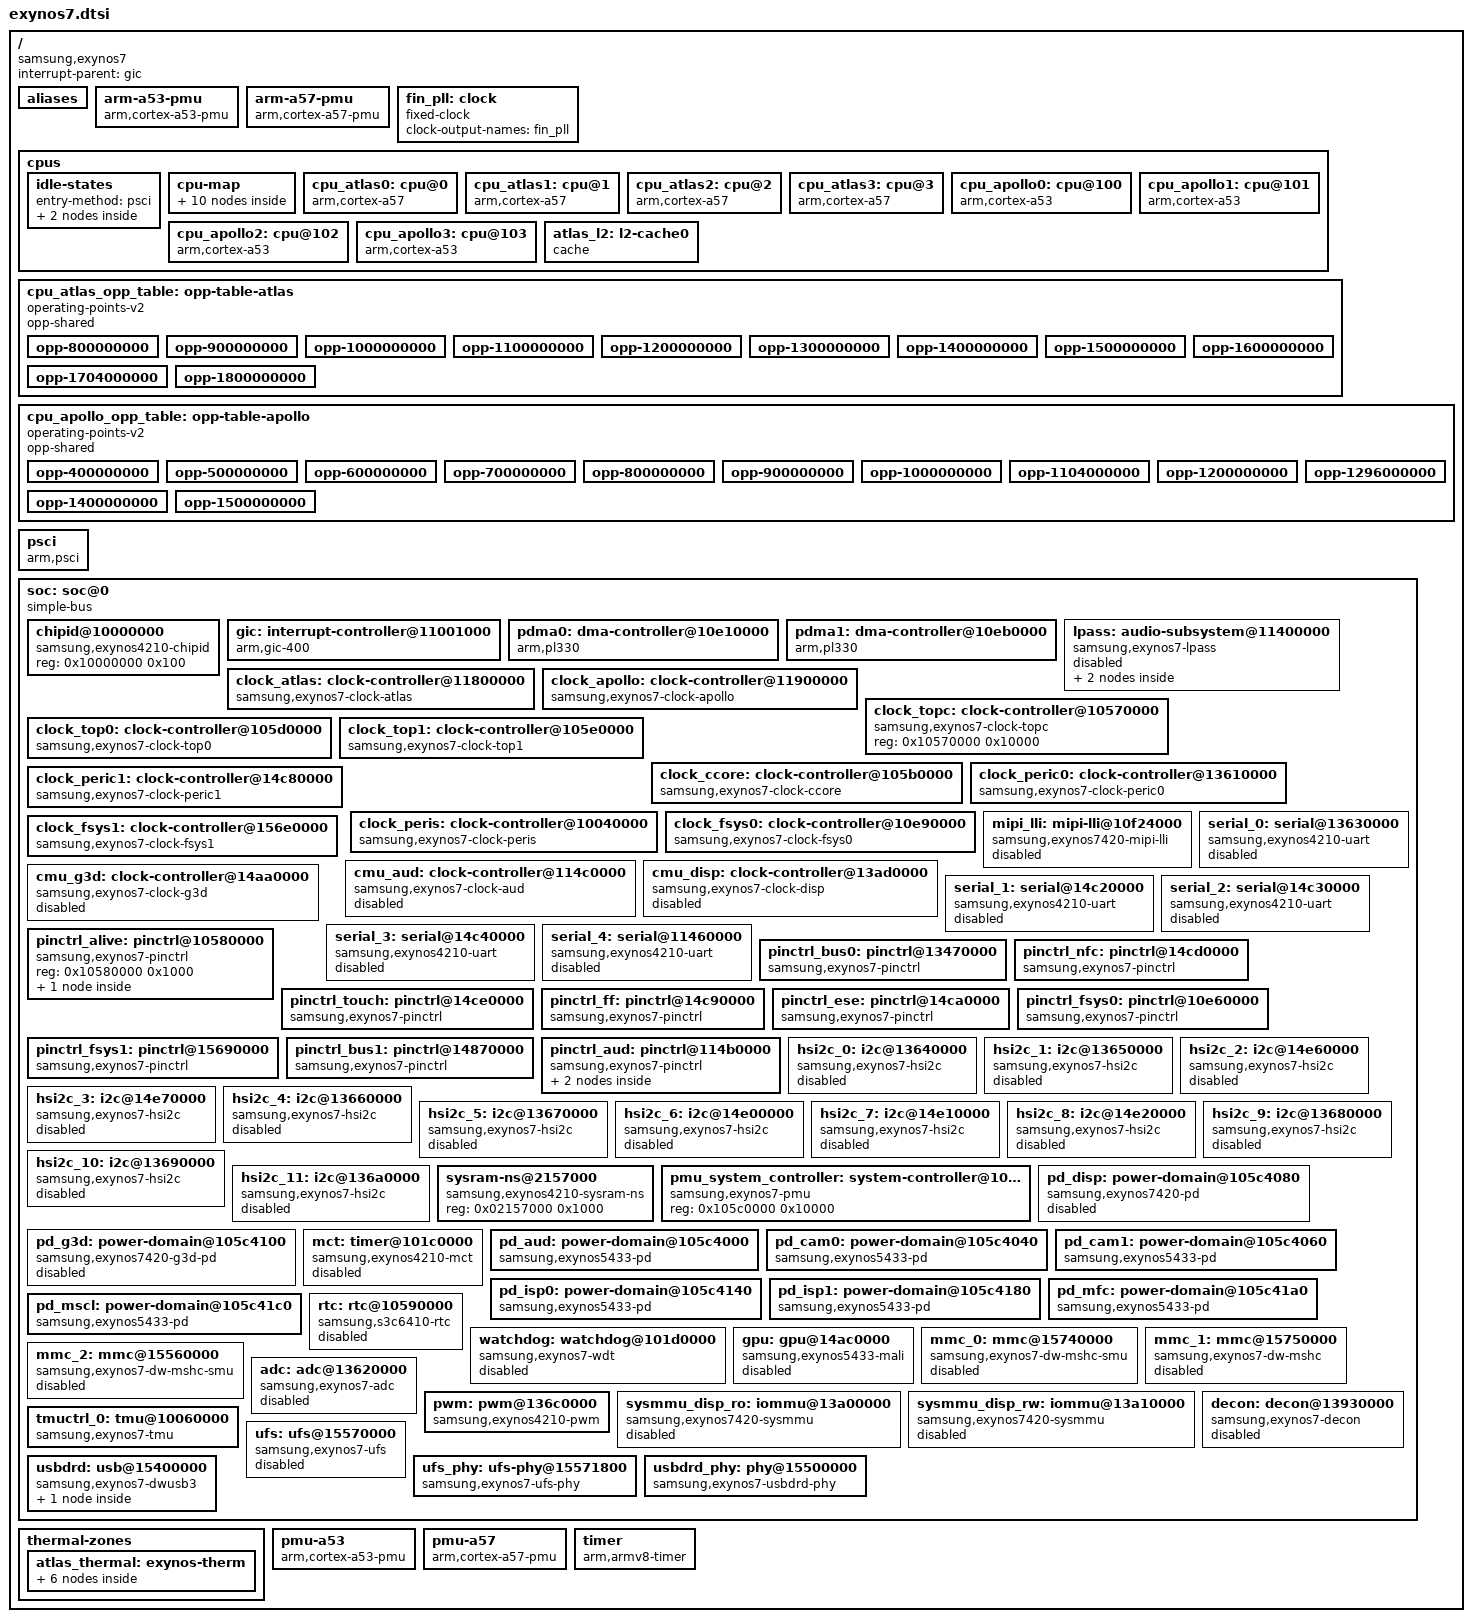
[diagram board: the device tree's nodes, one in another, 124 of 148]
// SPDX-License-Identifier: GPL-2.0
/*
 * Samsung Exynos7 SoC device tree source
 *
 * Copyright (c) 2014 Samsung Electronics Co., Ltd.
 *		http://www.samsung.com
 */

#include <dt-bindings/clock/exynos7-clk.h>
#include <dt-bindings/interrupt-controller/arm-gic.h>

/ {
	compatible = "samsung,exynos7";
	interrupt-parent = <&gic>;
	#address-cells = <2>;
	#size-cells = <2>;

	aliases {
		pinctrl0 = &pinctrl_alive;
		pinctrl1 = &pinctrl_bus0;
		pinctrl2 = &pinctrl_nfc;
		pinctrl3 = &pinctrl_touch;
		pinctrl4 = &pinctrl_ff;
		pinctrl5 = &pinctrl_ese;
		pinctrl6 = &pinctrl_fsys0;
		pinctrl7 = &pinctrl_fsys1;
		pinctrl8 = &pinctrl_bus1;
		pinctrl9 = &pinctrl_aud;
		tmuctrl0 = &tmuctrl_0;
	};

	arm-a53-pmu {
		compatible = "arm,cortex-a53-pmu";
		interrupts = <GIC_SPI 32 IRQ_TYPE_LEVEL_HIGH>,
			     <GIC_SPI 33 IRQ_TYPE_LEVEL_HIGH>,
			     <GIC_SPI 34 IRQ_TYPE_LEVEL_HIGH>,
			     <GIC_SPI 35 IRQ_TYPE_LEVEL_HIGH>;
		interrupt-affinity = <&cpu_apollo0>, <&cpu_apollo1>,
				     <&cpu_apollo2>, <&cpu_apollo3>;
	};

	arm-a57-pmu {
		compatible = "arm,cortex-a57-pmu";
		interrupts = <GIC_SPI 56 IRQ_TYPE_LEVEL_HIGH>,
			     <GIC_SPI 57 IRQ_TYPE_LEVEL_HIGH>,
			     <GIC_SPI 58 IRQ_TYPE_LEVEL_HIGH>,
			     <GIC_SPI 59 IRQ_TYPE_LEVEL_HIGH>;
		interrupt-affinity = <&cpu_atlas0>, <&cpu_atlas1>,
				     <&cpu_atlas2>, <&cpu_atlas3>;
	};

	fin_pll: clock {
		/* XXTI */
		compatible = "fixed-clock";
		clock-output-names = "fin_pll";
		#clock-cells = <0>;
	};

	cpus {
		#address-cells = <1>;
		#size-cells = <0>;

		/*
		 * Core power-down (C2) through PSCI 0.1 CPU_SUSPEND. The
		 * parameter asks for a power-down state, so the kernel saves
		 * the core's context; the PMU notifier in exynos-pmu clears
		 * the core's LOCAL_PWR_CFG for it. Residencies are the stock
		 * kernel's.
		 */
		idle-states {
			entry-method = "psci";

			CPU_C2_A57: cpu-c2-a57 {
				compatible = "arm,idle-state";
				arm,psci-suspend-param = <0x00010000>;
				entry-latency-us = <30>;
				exit-latency-us = <70>;
				min-residency-us = <2000>;
			};

			CPU_C2_A53: cpu-c2-a53 {
				compatible = "arm,idle-state";
				arm,psci-suspend-param = <0x00010000>;
				entry-latency-us = <30>;
				exit-latency-us = <70>;
				min-residency-us = <750>;
			};
		};

		/*
		 * Two clusters. Without the map and the per-MHz capacities the
		 * scheduler treats the eight cores as equal one-core clusters.
		 * The A53's efficiency, 677 per MHz to the A57's 1000, is the
		 * CoreMark value measured on a G920F (nk7420 calibration). With
		 * the top OPPs, 1.5 GHz on the A53s and 1.8 GHz on the A57s, it
		 * gives capacities of 578 and 1024.
		 */
		cpu-map {
			cluster0 {
				core0 { cpu = <&cpu_atlas0>; };
				core1 { cpu = <&cpu_atlas1>; };
				core2 { cpu = <&cpu_atlas2>; };
				core3 { cpu = <&cpu_atlas3>; };
			};

			cluster1 {
				core0 { cpu = <&cpu_apollo0>; };
				core1 { cpu = <&cpu_apollo1>; };
				core2 { cpu = <&cpu_apollo2>; };
				core3 { cpu = <&cpu_apollo3>; };
			};
		};

		/*
		 * Linux makes the boot CPU, the first A53 (MPIDR 0x100), CPU 0 and
		 * numbers the others in node order. Listing the A57s first gives
		 * A57 = CPUs 1-4 and A53 = CPUs 0 and 5-7, the numbering the
		 * cpufreq, memlat and power work on this branch was measured with.
		 */
		cpu_atlas0: cpu@0 {
			device_type = "cpu";
			compatible = "arm,cortex-a57";
			reg = <0x0>;
			enable-method = "psci";
			cpu-idle-states = <&CPU_C2_A57>;
			capacity-dmips-mhz = <1000>;
			clocks = <&clock_atlas CLK_SCLK_ATLAS>;
			operating-points-v2 = <&cpu_atlas_opp_table>;
			#cooling-cells = <2>;
			i-cache-size = <0xc000>;
			i-cache-line-size = <64>;
			i-cache-sets = <256>;
			d-cache-size = <0x8000>;
			d-cache-line-size = <64>;
			d-cache-sets = <256>;
			next-level-cache = <&atlas_l2>;
		};

		cpu_atlas1: cpu@1 {
			device_type = "cpu";
			compatible = "arm,cortex-a57";
			reg = <0x1>;
			enable-method = "psci";
			cpu-idle-states = <&CPU_C2_A57>;
			capacity-dmips-mhz = <1000>;
			clocks = <&clock_atlas CLK_SCLK_ATLAS>;
			operating-points-v2 = <&cpu_atlas_opp_table>;
			#cooling-cells = <2>;
			i-cache-size = <0xc000>;
			i-cache-line-size = <64>;
			i-cache-sets = <256>;
			d-cache-size = <0x8000>;
			d-cache-line-size = <64>;
			d-cache-sets = <256>;
			next-level-cache = <&atlas_l2>;
		};

		cpu_atlas2: cpu@2 {
			device_type = "cpu";
			compatible = "arm,cortex-a57";
			reg = <0x2>;
			enable-method = "psci";
			cpu-idle-states = <&CPU_C2_A57>;
			capacity-dmips-mhz = <1000>;
			clocks = <&clock_atlas CLK_SCLK_ATLAS>;
			operating-points-v2 = <&cpu_atlas_opp_table>;
			#cooling-cells = <2>;
			i-cache-size = <0xc000>;
			i-cache-line-size = <64>;
			i-cache-sets = <256>;
			d-cache-size = <0x8000>;
			d-cache-line-size = <64>;
			d-cache-sets = <256>;
			next-level-cache = <&atlas_l2>;
		};

		cpu_atlas3: cpu@3 {
			device_type = "cpu";
			compatible = "arm,cortex-a57";
			reg = <0x3>;
			enable-method = "psci";
			cpu-idle-states = <&CPU_C2_A57>;
			capacity-dmips-mhz = <1000>;
			clocks = <&clock_atlas CLK_SCLK_ATLAS>;
			operating-points-v2 = <&cpu_atlas_opp_table>;
			#cooling-cells = <2>;
			i-cache-size = <0xc000>;
			i-cache-line-size = <64>;
			i-cache-sets = <256>;
			d-cache-size = <0x8000>;
			d-cache-line-size = <64>;
			d-cache-sets = <256>;
			next-level-cache = <&atlas_l2>;
		};

		cpu_apollo0: cpu@100 {
			device_type = "cpu";
			compatible = "arm,cortex-a53";
			reg = <0x100>;
			enable-method = "psci";
			cpu-idle-states = <&CPU_C2_A53>;
			capacity-dmips-mhz = <677>;
			clocks = <&clock_apollo CLK_SCLK_APOLLO>;
			operating-points-v2 = <&cpu_apollo_opp_table>;
			#cooling-cells = <2>;
		};

		cpu_apollo1: cpu@101 {
			device_type = "cpu";
			compatible = "arm,cortex-a53";
			reg = <0x101>;
			enable-method = "psci";
			cpu-idle-states = <&CPU_C2_A53>;
			capacity-dmips-mhz = <677>;
			clocks = <&clock_apollo CLK_SCLK_APOLLO>;
			operating-points-v2 = <&cpu_apollo_opp_table>;
			#cooling-cells = <2>;
		};

		cpu_apollo2: cpu@102 {
			device_type = "cpu";
			compatible = "arm,cortex-a53";
			reg = <0x102>;
			enable-method = "psci";
			cpu-idle-states = <&CPU_C2_A53>;
			capacity-dmips-mhz = <677>;
			clocks = <&clock_apollo CLK_SCLK_APOLLO>;
			operating-points-v2 = <&cpu_apollo_opp_table>;
			#cooling-cells = <2>;
		};

		cpu_apollo3: cpu@103 {
			device_type = "cpu";
			compatible = "arm,cortex-a53";
			reg = <0x103>;
			enable-method = "psci";
			cpu-idle-states = <&CPU_C2_A53>;
			capacity-dmips-mhz = <677>;
			clocks = <&clock_apollo CLK_SCLK_APOLLO>;
			operating-points-v2 = <&cpu_apollo_opp_table>;
			#cooling-cells = <2>;
		};

		atlas_l2: l2-cache0 {
			compatible = "cache";
			cache-level = <2>;
			cache-unified;
			cache-size = <0x200000>;
			cache-line-size = <64>;
			cache-sets = <2048>;
		};
	};

	/*
	 * Cluster DVFS: the stock enabled ranges with the stock fallback
	 * voltages, which are at or above every fused ASV group. Atlas stops
	 * at 1.8 GHz while the PMIC's SRAM-rail tracking is left as S-Boot
	 * programmed it; above 1.125 V it must be switched.
	 *
	 * opp-microwatt is the energy model: per-core power measured on a
	 * G920F (calibration run 20260809T115944Z), plus a quarter of the
	 * measured shared-cluster power, since the energy model has no
	 * cluster term. It was measured at that phone's fused ASV voltages,
	 * so absolute power here is somewhat low; the ratio between the
	 * clusters, which energy-aware scheduling uses, is what matters.
	 */
	cpu_atlas_opp_table: opp-table-atlas {
		compatible = "operating-points-v2";
		opp-shared;

		opp-800000000 {
			opp-hz = /bits/ 64 <800000000>;
			opp-microvolt = <825000>;
			opp-microwatt = <261750>;
			clock-latency-ns = <500000>;
		};

		opp-900000000 {
			opp-hz = /bits/ 64 <900000000>;
			opp-microvolt = <850000>;
			opp-microwatt = <304500>;
			clock-latency-ns = <500000>;
		};

		opp-1000000000 {
			opp-hz = /bits/ 64 <1000000000>;
			opp-microvolt = <875000>;
			opp-microwatt = <359500>;
			clock-latency-ns = <500000>;
		};

		opp-1100000000 {
			opp-hz = /bits/ 64 <1100000000>;
			opp-microvolt = <900000>;
			opp-microwatt = <428250>;
			clock-latency-ns = <500000>;
		};

		opp-1200000000 {
			opp-hz = /bits/ 64 <1200000000>;
			opp-microvolt = <925000>;
			opp-microwatt = <493250>;
			clock-latency-ns = <500000>;
		};

		opp-1300000000 {
			opp-hz = /bits/ 64 <1300000000>;
			opp-microvolt = <950000>;
			opp-microwatt = <563250>;
			clock-latency-ns = <500000>;
		};

		opp-1400000000 {
			opp-hz = /bits/ 64 <1400000000>;
			opp-microvolt = <981250>;
			opp-microwatt = <654000>;
			clock-latency-ns = <500000>;
		};

		opp-1500000000 {
			opp-hz = /bits/ 64 <1500000000>;
			opp-microvolt = <1012500>;
			opp-microwatt = <737000>;
			clock-latency-ns = <500000>;
		};

		opp-1600000000 {
			opp-hz = /bits/ 64 <1600000000>;
			opp-microvolt = <1043750>;
			opp-microwatt = <855000>;
			clock-latency-ns = <500000>;
		};

		opp-1704000000 {
			opp-hz = /bits/ 64 <1704000000>;
			opp-microvolt = <1081250>;
			opp-microwatt = <989750>;
			clock-latency-ns = <500000>;
		};

		opp-1800000000 {
			opp-hz = /bits/ 64 <1800000000>;
			opp-microvolt = <1118750>;
			opp-microwatt = <1156750>;
			clock-latency-ns = <500000>;
		};
	};

	cpu_apollo_opp_table: opp-table-apollo {
		compatible = "operating-points-v2";
		opp-shared;

		opp-400000000 {
			opp-hz = /bits/ 64 <400000000>;
			opp-microvolt = <675000>;
			opp-microwatt = <25000>;
			clock-latency-ns = <500000>;
		};

		opp-500000000 {
			opp-hz = /bits/ 64 <500000000>;
			opp-microvolt = <712500>;
			opp-microwatt = <35000>;
			clock-latency-ns = <500000>;
		};

		opp-600000000 {
			opp-hz = /bits/ 64 <600000000>;
			opp-microvolt = <750000>;
			opp-microwatt = <43000>;
			clock-latency-ns = <500000>;
		};

		opp-700000000 {
			opp-hz = /bits/ 64 <700000000>;
			opp-microvolt = <787500>;
			opp-microwatt = <54000>;
			clock-latency-ns = <500000>;
		};

		opp-800000000 {
			opp-hz = /bits/ 64 <800000000>;
			opp-microvolt = <825000>;
			opp-microwatt = <66000>;
			clock-latency-ns = <500000>;
		};

		opp-900000000 {
			opp-hz = /bits/ 64 <900000000>;
			opp-microvolt = <862500>;
			opp-microwatt = <81000>;
			clock-latency-ns = <500000>;
		};

		opp-1000000000 {
			opp-hz = /bits/ 64 <1000000000>;
			opp-microvolt = <900000>;
			opp-microwatt = <96000>;
			clock-latency-ns = <500000>;
		};

		opp-1104000000 {
			opp-hz = /bits/ 64 <1104000000>;
			opp-microvolt = <943750>;
			opp-microwatt = <117000>;
			clock-latency-ns = <500000>;
		};

		opp-1200000000 {
			opp-hz = /bits/ 64 <1200000000>;
			opp-microvolt = <981250>;
			opp-microwatt = <140250>;
			clock-latency-ns = <500000>;
		};

		opp-1296000000 {
			opp-hz = /bits/ 64 <1296000000>;
			opp-microvolt = <1018750>;
			opp-microwatt = <166250>;
			clock-latency-ns = <500000>;
		};

		opp-1400000000 {
			opp-hz = /bits/ 64 <1400000000>;
			opp-microvolt = <1068750>;
			opp-microwatt = <200250>;
			clock-latency-ns = <500000>;
		};

		opp-1500000000 {
			opp-hz = /bits/ 64 <1500000000>;
			opp-microvolt = <1118750>;
			opp-microwatt = <237250>;
			clock-latency-ns = <500000>;
		};
	};

	psci {
		compatible = "arm,psci";
		method = "smc";
		cpu_suspend = <0xc4000001>;
		cpu_off = <0x84000002>;
		cpu_on = <0xc4000003>;
	};

	soc: soc@0 {
		compatible = "simple-bus";
		#address-cells = <1>;
		#size-cells = <1>;
		ranges = <0 0 0 0x18000000>;

		chipid@10000000 {
			compatible = "samsung,exynos4210-chipid";
			reg = <0x10000000 0x100>;
		};

		gic: interrupt-controller@11001000 {
			compatible = "arm,gic-400";
			#interrupt-cells = <3>;
			#address-cells = <0>;
			interrupt-controller;
			reg = <0x11001000 0x1000>,
			      <0x11002000 0x2000>,
			      <0x11004000 0x2000>,
			      <0x11006000 0x2000>;
		};

		pdma0: dma-controller@10e10000 {
			compatible = "arm,pl330", "arm,primecell";
			reg = <0x10e10000 0x1000>;
			interrupts = <GIC_SPI 225 IRQ_TYPE_LEVEL_HIGH>;
			clocks = <&clock_fsys0 ACLK_PDMA0>;
			clock-names = "apb_pclk";
			#dma-cells = <1>;
		};

		pdma1: dma-controller@10eb0000 {
			compatible = "arm,pl330", "arm,primecell";
			reg = <0x10eb0000 0x1000>;
			interrupts = <GIC_SPI 226 IRQ_TYPE_LEVEL_HIGH>;
			clocks = <&clock_fsys0 ACLK_PDMA1>;
			clock-names = "apb_pclk";
			#dma-cells = <1>;
		};

		/*
		 * LPASS routes the DMA and I2S interrupts to the CPU and holds
		 * their resets. The UART at 0x11460000 (serial_4) is in the
		 * same block but stays outside this node; the exynos7 variant
		 * of the driver leaves it alone. The second reg is the AUD
		 * SysMMU, which the driver sets to bypass. The clocks keep the
		 * SysMMU and the bridge to the top bus, the ADMA's path out,
		 * running while LPASS is up.
		 */
		lpass: audio-subsystem@11400000 {
			compatible = "samsung,exynos7-lpass";
			reg = <0x11400000 0x100>, <0x114e0000 0x100>;
			clocks = <&cmu_aud PCLK_SMMU_AUD>,
				 <&cmu_aud ACLK_SMMU_AUD>,
				 <&cmu_aud ACLK_ACEL_LH_ASYNC_SI_TOP>;
			clock-names = "smmu_pclk", "smmu_aclk", "async_aclk";
			#address-cells = <1>;
			#size-cells = <1>;
			ranges;
			status = "disabled";

			adma: dma-controller@11420000 {
				compatible = "arm,pl330", "arm,primecell";
				reg = <0x11420000 0x1000>;
				interrupts = <GIC_SPI 97 IRQ_TYPE_LEVEL_HIGH>;
				clocks = <&cmu_aud ACLK_ADMA>;
				clock-names = "apb_pclk";
				#dma-cells = <1>;
			};

			i2s0: i2s@11440000 {
				compatible = "samsung,exynos7-i2s";
				reg = <0x11440000 0x100>;
				interrupts = <GIC_SPI 70 IRQ_TYPE_LEVEL_HIGH>;
				dmas = <&adma 0>, <&adma 2>;
				dma-names = "tx", "rx";
				clocks = <&cmu_aud PCLK_I2S>, <&cmu_aud SCLK_I2S>,
					 <&cmu_aud SCLK_I2S>;
				clock-names = "iis", "i2s_opclk0", "i2s_opclk1";
				#sound-dai-cells = <1>;
				status = "disabled";
			};
		};

		clock_atlas: clock-controller@11800000 {
			compatible = "samsung,exynos7-clock-atlas";
			reg = <0x11800000 0x2000>;
			#clock-cells = <1>;
			clocks = <&fin_pll>;
			clock-names = "fin_pll";
		};

		clock_apollo: clock-controller@11900000 {
			compatible = "samsung,exynos7-clock-apollo";
			reg = <0x11900000 0x2000>;
			#clock-cells = <1>;
			clocks = <&fin_pll>;
			clock-names = "fin_pll";
		};

		clock_topc: clock-controller@10570000 {
			compatible = "samsung,exynos7-clock-topc";
			reg = <0x10570000 0x10000>;
			#clock-cells = <1>;
		};

		clock_top0: clock-controller@105d0000 {
			compatible = "samsung,exynos7-clock-top0";
			reg = <0x105d0000 0xb000>;
			#clock-cells = <1>;
			clocks = <&fin_pll>, <&clock_topc DOUT_SCLK_BUS0_PLL>,
				 <&clock_topc DOUT_SCLK_BUS1_PLL>,
				 <&clock_topc DOUT_SCLK_CC_PLL>,
				 <&clock_topc DOUT_SCLK_MFC_PLL>,
				 <&clock_topc DOUT_SCLK_AUD_PLL>;
			clock-names = "fin_pll", "dout_sclk_bus0_pll",
				      "dout_sclk_bus1_pll", "dout_sclk_cc_pll",
				      "dout_sclk_mfc_pll", "dout_sclk_aud_pll";
		};

		clock_top1: clock-controller@105e0000 {
			compatible = "samsung,exynos7-clock-top1";
			reg = <0x105e0000 0xb000>;
			#clock-cells = <1>;
			clocks = <&fin_pll>, <&clock_topc DOUT_SCLK_BUS0_PLL>,
				 <&clock_topc DOUT_SCLK_BUS1_PLL>,
				 <&clock_topc DOUT_SCLK_CC_PLL>,
				 <&clock_topc DOUT_SCLK_MFC_PLL>;
			clock-names = "fin_pll", "dout_sclk_bus0_pll",
				      "dout_sclk_bus1_pll", "dout_sclk_cc_pll",
				      "dout_sclk_mfc_pll";
		};

		clock_ccore: clock-controller@105b0000 {
			compatible = "samsung,exynos7-clock-ccore";
			reg = <0x105b0000 0xd00>;
			#clock-cells = <1>;
			clocks = <&fin_pll>, <&clock_topc DOUT_ACLK_CCORE_133>;
			clock-names = "fin_pll", "dout_aclk_ccore_133";
		};

		clock_peric0: clock-controller@13610000 {
			compatible = "samsung,exynos7-clock-peric0";
			reg = <0x13610000 0xd00>;
			#clock-cells = <1>;
			clocks = <&fin_pll>, <&clock_top0 DOUT_ACLK_PERIC0>,
				 <&clock_top0 CLK_SCLK_UART0>;
			clock-names = "fin_pll", "dout_aclk_peric0_66",
				      "sclk_uart0";
		};

		clock_peric1: clock-controller@14c80000 {
			compatible = "samsung,exynos7-clock-peric1";
			reg = <0x14c80000 0xd00>;
			#clock-cells = <1>;
			clocks = <&fin_pll>,
				 <&clock_top0 DOUT_ACLK_PERIC1>,
				 <&clock_top0 CLK_SCLK_UART1>,
				 <&clock_top0 CLK_SCLK_UART2>,
				 <&clock_top0 CLK_SCLK_UART3>,
				 <&clock_top0 CLK_SCLK_SPI0>,
				 <&clock_top0 CLK_SCLK_SPI1>,
				 <&clock_top0 CLK_SCLK_SPI2>,
				 <&clock_top0 CLK_SCLK_SPI3>,
				 <&clock_top0 CLK_SCLK_SPI4>,
				 <&clock_top0 CLK_SCLK_I2S1>,
				 <&clock_top0 CLK_SCLK_PCM1>,
				 <&clock_top0 CLK_SCLK_SPDIF>;
			clock-names = "fin_pll",
				      "dout_aclk_peric1_66",
				      "sclk_uart1",
				      "sclk_uart2",
				      "sclk_uart3",
				      "sclk_spi0",
				      "sclk_spi1",
				      "sclk_spi2",
				      "sclk_spi3",
				      "sclk_spi4",
				      "sclk_i2s1",
				      "sclk_pcm1",
				      "sclk_spdif";
		};

		clock_peris: clock-controller@10040000 {
			compatible = "samsung,exynos7-clock-peris";
			reg = <0x10040000 0xd00>;
			#clock-cells = <1>;
			clocks = <&fin_pll>, <&clock_topc DOUT_ACLK_PERIS>;
			clock-names = "fin_pll", "dout_aclk_peris_66";
		};

		clock_fsys0: clock-controller@10e90000 {
			compatible = "samsung,exynos7-clock-fsys0";
			reg = <0x10e90000 0xd00>;
			#clock-cells = <1>;
			clocks = <&fin_pll>, <&clock_top1 DOUT_ACLK_FSYS0_200>,
				 <&clock_top1 DOUT_SCLK_MMC2>;
			clock-names = "fin_pll", "dout_aclk_fsys0_200",
				      "dout_sclk_mmc2";
		};

		/*
		 * MIPI-LLI to the modem CP. Register windows, interrupts and
		 * clocks from the stock tw70-stock exynos7420.dtsi node; the
		 * M-PHY (stock "mphy" child) is folded into "phy" and "pma".
		 * The combo PHY PMA at 0x10ed0000 is shared with PCIe channel 0,
		 * which this tree does not use. Boards add the IPC carve-out
		 * (memory-region) and the M-PHY settings.
		 */
		mipi_lli: mipi-lli@10f24000 {
			compatible = "samsung,exynos7420-mipi-lli";
			reg = <0x10f24000 0x4000>,
			      <0x10f34000 0x4000>,
			      <0x10050000 0x2000>,
			      <0x10f20000 0x4000>,
			      <0x10ed0000 0x200>;
			reg-names = "lli", "remote", "sysreg", "phy", "pma";
			interrupts = <GIC_SPI 208 IRQ_TYPE_LEVEL_HIGH>,
				     <GIC_SPI 209 IRQ_TYPE_LEVEL_HIGH>;
			interrupt-names = "lli", "sig";
			samsung,pmu-syscon = <&pmu_system_controller 0x724>;
			clocks = <&clock_fsys0 ACLK_XIU_MODEMX>,
				 <&clock_fsys0 ACLK_COMBO_PHY_MODEM_PCS_PCLK>,
				 <&clock_fsys0 SCLK_PHY_FSYS0>,
				 <&clock_fsys0 SCLK_COMBO_PHY_MODEM_26M>,
				 <&clock_fsys0 PCLK_ASYNC_COMBO_PHY_MODEM>,
				 <&clock_fsys0 ACLK_XIU_LLISFRX>,
				 <&clock_fsys0 ACLK_AXIUS_LLI_BE>,
				 <&clock_fsys0 ACLK_AXIUS_LLI_LL>,
				 <&clock_fsys0 ACLK_AXIUS_LLISFRX_LLILL>,
				 <&clock_fsys0 ACLK_AXIUS_LLISFRX_LLIBE>,
				 <&clock_fsys0 ACLK_LLI_SVC_LOC>,
				 <&clock_fsys0 ACLK_LLI_SVC_REM>,
				 <&clock_fsys0 ACLK_LLI_LL_INIT>,
				 <&clock_fsys0 ACLK_LLI_BE_INIT>,
				 <&clock_fsys0 ACLK_LLI_LL_TARG>,
				 <&clock_fsys0 ACLK_LLI_BE_TARG>,
				 <&clock_fsys0 PHYCLK_LLI_TX0_SYMBOL_USER>,
				 <&clock_fsys0 PHYCLK_LLI_RX0_SYMBOL_USER>;
			clock-names = "aclk_xiu_modemx",
				      "aclk_combo_phy_modem_pcs_pclk",
				      "sclk_phy_fsys0",
				      "sclk_combo_phy_modem_26m",
				      "pclk_async_combo_phy_modem",
				      "aclk_xiu_llisfrx",
				      "aclk_axius_lli_be",
				      "aclk_axius_lli_ll",
				      "aclk_axius_llisfrx_llill",
				      "aclk_axius_llisfrx_llibe",
				      "aclk_lli_svc_loc",
				      "aclk_lli_svc_rem",
				      "aclk_lli_ll_init",
				      "aclk_lli_be_init",
				      "aclk_lli_ll_targ",
				      "aclk_lli_be_targ",
				      "user_phyclk_lli_tx0_symbol",
				      "user_phyclk_lli_rx0_symbol";
			/*
			 * Stock USERMUX clocks: select the PHY-side symbol clocks.
			 * mout_sclk_phy_fsys0_user keeps the bootloader setting,
			 * because its parent sits in CMU_TOP1, which boards may
			 * leave unregistered.
			 */
			assigned-clocks = <&clock_fsys0 MOUT_PHYCLK_LLI_TX0_USER>,
					  <&clock_fsys0 MOUT_PHYCLK_LLI_RX0_USER>;
			assigned-clock-parents = <&clock_fsys0 PHYCLK_LLI_TX0>,
						 <&clock_fsys0 PHYCLK_LLI_RX0>;
			status = "disabled";
		};

		clock_fsys1: clock-controller@156e0000 {
			compatible = "samsung,exynos7-clock-fsys1";
			reg = <0x156e0000 0xd00>;
			#clock-cells = <1>;
			clocks = <&fin_pll>, <&clock_top1 DOUT_ACLK_FSYS1_200>,
				 <&clock_top1 DOUT_SCLK_MMC0>,
				 <&clock_top1 DOUT_SCLK_MMC1>,
				 <&clock_top1 DOUT_SCLK_UFSUNIPRO20>,
				 <&clock_top1 DOUT_SCLK_PHY_FSYS1>,
				 <&clock_top1 DOUT_SCLK_PHY_FSYS1_26M>;
			clock-names = "fin_pll", "dout_aclk_fsys1_200",
				      "dout_sclk_mmc0", "dout_sclk_mmc1",
				      "dout_sclk_ufsunipro20", "dout_sclk_phy_fsys1",
				      "dout_sclk_phy_fsys1_26m";
		};

		cmu_aud: clock-controller@114c0000 {
			compatible = "samsung,exynos7-clock-aud";
			reg = <0x114c0000 0xd00>;
			#clock-cells = <1>;
			clocks = <&fin_pll>, <&clock_topc FOUT_AUD_PLL>;
			clock-names = "fin_pll", "fout_aud_pll";
			status = "disabled";
		};

		cmu_disp: clock-controller@13ad0000 {
			compatible = "samsung,exynos7-clock-disp";
			reg = <0x13ad0000 0xd00>;
			#clock-cells = <1>;
			clocks = <&fin_pll>, <&clock_top0 CLK_ACLK_DISP_400>,
				 <&clock_top0 CLK_SCLK_DECON_INT_ECLK>,
				 <&clock_top0 CLK_SCLK_DECON_VCLK>;
			clock-names = "fin_pll", "aclk_disp_400",
				      "sclk_decon_int_eclk", "sclk_decon_vclk";
			status = "disabled";
		};

		cmu_g3d: clock-controller@14aa0000 {
			compatible = "samsung,exynos7-clock-g3d";
			reg = <0x14aa0000 0xd00>;
			#clock-cells = <1>;
			clocks = <&fin_pll>;
			clock-names = "fin_pll";
			status = "disabled";
		};

		serial_0: serial@13630000 {
			compatible = "samsung,exynos4210-uart";
			reg = <0x13630000 0x100>;
			interrupts = <GIC_SPI 440 IRQ_TYPE_LEVEL_HIGH>;
			clocks = <&clock_peric0 PCLK_UART0>,
				 <&clock_peric0 SCLK_UART0>;
			clock-names = "uart", "clk_uart_baud0";
			status = "disabled";
		};

		serial_1: serial@14c20000 {
			compatible = "samsung,exynos4210-uart";
			reg = <0x14c20000 0x100>;
			interrupts = <GIC_SPI 456 IRQ_TYPE_LEVEL_HIGH>;
			clocks = <&clock_peric1 PCLK_UART1>,
				 <&clock_peric1 SCLK_UART1>;
			clock-names = "uart", "clk_uart_baud0";
			status = "disabled";
		};

		serial_2: serial@14c30000 {
			compatible = "samsung,exynos4210-uart";
			reg = <0x14c30000 0x100>;
			interrupts = <GIC_SPI 457 IRQ_TYPE_LEVEL_HIGH>;
			clocks = <&clock_peric1 PCLK_UART2>,
				 <&clock_peric1 SCLK_UART2>;
			clock-names = "uart", "clk_uart_baud0";
			status = "disabled";
		};

		serial_3: serial@14c40000 {
			compatible = "samsung,exynos4210-uart";
			reg = <0x14c40000 0x100>;
			interrupts = <GIC_SPI 458 IRQ_TYPE_LEVEL_HIGH>;
			clocks = <&clock_peric1 PCLK_UART3>,
				 <&clock_peric1 SCLK_UART3>;
			clock-names = "uart", "clk_uart_baud0";
			status = "disabled";
		};

		serial_4: serial@11460000 {
			compatible = "samsung,exynos4210-uart";
			reg = <0x11460000 0x100>;
			interrupts = <GIC_SPI 91 IRQ_TYPE_LEVEL_HIGH>;
			clocks = <&cmu_aud PCLK_UART>, <&cmu_aud SCLK_UART>;
			clock-names = "uart", "clk_uart_baud0";
			status = "disabled";
		};

		pinctrl_alive: pinctrl@10580000 {
			compatible = "samsung,exynos7-pinctrl";
			reg = <0x10580000 0x1000>;

			wakeup-interrupt-controller {
				compatible = "samsung,exynos7-wakeup-eint";
				interrupt-parent = <&gic>;
				interrupts = <GIC_SPI 16 IRQ_TYPE_LEVEL_HIGH>;
			};
		};

		pinctrl_bus0: pinctrl@13470000 {
			compatible = "samsung,exynos7-pinctrl";
			reg = <0x13470000 0x1000>;
			interrupts = <GIC_SPI 383 IRQ_TYPE_LEVEL_HIGH>;
		};

		pinctrl_nfc: pinctrl@14cd0000 {
			compatible = "samsung,exynos7-pinctrl";
			reg = <0x14cd0000 0x1000>;
			interrupts = <GIC_SPI 473 IRQ_TYPE_LEVEL_HIGH>;
		};

		pinctrl_touch: pinctrl@14ce0000 {
			compatible = "samsung,exynos7-pinctrl";
			reg = <0x14ce0000 0x1000>;
			interrupts = <GIC_SPI 474 IRQ_TYPE_LEVEL_HIGH>;
		};

		pinctrl_ff: pinctrl@14c90000 {
			compatible = "samsung,exynos7-pinctrl";
			reg = <0x14c90000 0x1000>;
			interrupts = <GIC_SPI 475 IRQ_TYPE_LEVEL_HIGH>;
		};

		pinctrl_ese: pinctrl@14ca0000 {
			compatible = "samsung,exynos7-pinctrl";
			reg = <0x14ca0000 0x1000>;
			interrupts = <GIC_SPI 476 IRQ_TYPE_LEVEL_HIGH>;
		};

		pinctrl_fsys0: pinctrl@10e60000 {
			compatible = "samsung,exynos7-pinctrl";
			reg = <0x10e60000 0x1000>;
			interrupts = <GIC_SPI 221 IRQ_TYPE_LEVEL_HIGH>;
		};

		pinctrl_fsys1: pinctrl@15690000 {
			compatible = "samsung,exynos7-pinctrl";
			reg = <0x15690000 0x1000>;
			interrupts = <GIC_SPI 203 IRQ_TYPE_LEVEL_HIGH>;
		};

		pinctrl_bus1: pinctrl@14870000 {
			compatible = "samsung,exynos7-pinctrl";
			reg = <0x14870000 0x1000>;
			interrupts = <GIC_SPI 384 IRQ_TYPE_LEVEL_HIGH>;
		};

		pinctrl_aud: pinctrl@114b0000 {
			compatible = "samsung,exynos7-pinctrl";
			reg = <0x114b0000 0x1000>;
			interrupts = <GIC_SPI 92 IRQ_TYPE_LEVEL_HIGH>;

			gpz0: gpz0-gpio-bank {
				gpio-controller;
				#gpio-cells = <2>;

				interrupt-controller;
				#interrupt-cells = <2>;
			};

			gpz1: gpz1-gpio-bank {
				gpio-controller;
				#gpio-cells = <2>;

				interrupt-controller;
				#interrupt-cells = <2>;
			};
		};

		hsi2c_0: i2c@13640000 {
			compatible = "samsung,exynos7-hsi2c";
			reg = <0x13640000 0x1000>;
			interrupts = <GIC_SPI 441 IRQ_TYPE_LEVEL_HIGH>;
			#address-cells = <1>;
			#size-cells = <0>;
			pinctrl-names = "default";
			pinctrl-0 = <&hs_i2c0_bus>;
			clocks = <&clock_peric0 PCLK_HSI2C0>;
			clock-names = "hsi2c";
			status = "disabled";
		};

		hsi2c_1: i2c@13650000 {
			compatible = "samsung,exynos7-hsi2c";
			reg = <0x13650000 0x1000>;
			interrupts = <GIC_SPI 442 IRQ_TYPE_LEVEL_HIGH>;
			#address-cells = <1>;
			#size-cells = <0>;
			pinctrl-names = "default";
			pinctrl-0 = <&hs_i2c1_bus>;
			clocks = <&clock_peric0 PCLK_HSI2C1>;
			clock-names = "hsi2c";
			status = "disabled";
		};

		hsi2c_2: i2c@14e60000 {
			compatible = "samsung,exynos7-hsi2c";
			reg = <0x14e60000 0x1000>;
			interrupts = <GIC_SPI 459 IRQ_TYPE_LEVEL_HIGH>;
			#address-cells = <1>;
			#size-cells = <0>;
			pinctrl-names = "default";
			pinctrl-0 = <&hs_i2c2_bus>;
			clocks = <&clock_peric1 PCLK_HSI2C2>;
			clock-names = "hsi2c";
			status = "disabled";
		};

		hsi2c_3: i2c@14e70000 {
			compatible = "samsung,exynos7-hsi2c";
			reg = <0x14e70000 0x1000>;
			interrupts = <GIC_SPI 460 IRQ_TYPE_LEVEL_HIGH>;
			#address-cells = <1>;
			#size-cells = <0>;
			pinctrl-names = "default";
			pinctrl-0 = <&hs_i2c3_bus>;
			clocks = <&clock_peric1 PCLK_HSI2C3>;
			clock-names = "hsi2c";
			status = "disabled";
		};

		hsi2c_4: i2c@13660000 {
			compatible = "samsung,exynos7-hsi2c";
			reg = <0x13660000 0x1000>;
			interrupts = <GIC_SPI 443 IRQ_TYPE_LEVEL_HIGH>;
			#address-cells = <1>;
			#size-cells = <0>;
			pinctrl-names = "default";
			pinctrl-0 = <&hs_i2c4_bus>;
			clocks = <&clock_peric0 PCLK_HSI2C4>;
			clock-names = "hsi2c";
			status = "disabled";
		};

		hsi2c_5: i2c@13670000 {
			compatible = "samsung,exynos7-hsi2c";
			reg = <0x13670000 0x1000>;
			interrupts = <GIC_SPI 444 IRQ_TYPE_LEVEL_HIGH>;
			#address-cells = <1>;
			#size-cells = <0>;
			pinctrl-names = "default";
			pinctrl-0 = <&hs_i2c5_bus>;
			clocks = <&clock_peric0 PCLK_HSI2C5>;
			clock-names = "hsi2c";
			status = "disabled";
		};

		hsi2c_6: i2c@14e00000 {
			compatible = "samsung,exynos7-hsi2c";
			reg = <0x14e00000 0x1000>;
			interrupts = <GIC_SPI 461 IRQ_TYPE_LEVEL_HIGH>;
			#address-cells = <1>;
			#size-cells = <0>;
			pinctrl-names = "default";
			pinctrl-0 = <&hs_i2c6_bus>;
			clocks = <&clock_peric1 PCLK_HSI2C6>;
			clock-names = "hsi2c";
			status = "disabled";
		};

		hsi2c_7: i2c@14e10000 {
			compatible = "samsung,exynos7-hsi2c";
			reg = <0x14e10000 0x1000>;
			interrupts = <GIC_SPI 462 IRQ_TYPE_LEVEL_HIGH>;
			#address-cells = <1>;
			#size-cells = <0>;
			pinctrl-names = "default";
			pinctrl-0 = <&hs_i2c7_bus>;
			clocks = <&clock_peric1 PCLK_HSI2C7>;
			clock-names = "hsi2c";
			status = "disabled";
		};

		hsi2c_8: i2c@14e20000 {
			compatible = "samsung,exynos7-hsi2c";
			reg = <0x14e20000 0x1000>;
			interrupts = <GIC_SPI 463 IRQ_TYPE_LEVEL_HIGH>;
			#address-cells = <1>;
			#size-cells = <0>;
			pinctrl-names = "default";
			pinctrl-0 = <&hs_i2c8_bus>;
			clocks = <&clock_peric1 PCLK_HSI2C8>;
			clock-names = "hsi2c";
			status = "disabled";
		};

		hsi2c_9: i2c@13680000 {
			compatible = "samsung,exynos7-hsi2c";
			reg = <0x13680000 0x1000>;
			interrupts = <GIC_SPI 445 IRQ_TYPE_LEVEL_HIGH>;
			#address-cells = <1>;
			#size-cells = <0>;
			pinctrl-names = "default";
			pinctrl-0 = <&hs_i2c9_bus>;
			clocks = <&clock_peric0 PCLK_HSI2C9>;
			clock-names = "hsi2c";
			status = "disabled";
		};

		hsi2c_10: i2c@13690000 {
			compatible = "samsung,exynos7-hsi2c";
			reg = <0x13690000 0x1000>;
			interrupts = <GIC_SPI 446 IRQ_TYPE_LEVEL_HIGH>;
			#address-cells = <1>;
			#size-cells = <0>;
			pinctrl-names = "default";
			pinctrl-0 = <&hs_i2c10_bus>;
			clocks = <&clock_peric0 PCLK_HSI2C10>;
			clock-names = "hsi2c";
			status = "disabled";
		};

		hsi2c_11: i2c@136a0000 {
			compatible = "samsung,exynos7-hsi2c";
			reg = <0x136a0000 0x1000>;
			interrupts = <GIC_SPI 447 IRQ_TYPE_LEVEL_HIGH>;
			#address-cells = <1>;
			#size-cells = <0>;
			pinctrl-names = "default";
			pinctrl-0 = <&hs_i2c11_bus>;
			clocks = <&clock_peric0 PCLK_HSI2C11>;
			clock-names = "hsi2c";
			status = "disabled";
		};

		/* Non-secure SYSRAM: INFORM words shared with the firmware. */
		sysram-ns@2157000 {
			compatible = "samsung,exynos4210-sysram-ns";
			reg = <0x02157000 0x1000>;
		};

		pmu_system_controller: system-controller@105c0000 {
			compatible = "samsung,exynos7-pmu", "syscon";
			reg = <0x105c0000 0x10000>;
		};

		pd_disp: power-domain@105c4080 {
			compatible = "samsung,exynos7420-pd";
			reg = <0x105c4080 0x20>;
			#power-domain-cells = <0>;
			label = "disp";
			status = "disabled";
		};

		pd_g3d: power-domain@105c4100 {
			compatible = "samsung,exynos7420-g3d-pd",
				     "samsung,exynos5433-pd";
			reg = <0x105c4100 0x20>;
			#power-domain-cells = <0>;
			label = "g3d";
			status = "disabled";
		};

		mct: timer@101c0000 {
			compatible = "samsung,exynos4210-mct";
			reg = <0x101c0000 0x800>;
			interrupts = <GIC_SPI 112 IRQ_TYPE_LEVEL_HIGH>,
				     <GIC_SPI 113 IRQ_TYPE_LEVEL_HIGH>,
				     <GIC_SPI 114 IRQ_TYPE_LEVEL_HIGH>,
				     <GIC_SPI 115 IRQ_TYPE_LEVEL_HIGH>,
				     <GIC_SPI 116 IRQ_TYPE_LEVEL_HIGH>,
				     <GIC_SPI 117 IRQ_TYPE_LEVEL_HIGH>,
				     <GIC_SPI 118 IRQ_TYPE_LEVEL_HIGH>,
				     <GIC_SPI 119 IRQ_TYPE_LEVEL_HIGH>,
				     <GIC_SPI 120 IRQ_TYPE_LEVEL_HIGH>,
				     <GIC_SPI 121 IRQ_TYPE_LEVEL_HIGH>,
				     <GIC_SPI 122 IRQ_TYPE_LEVEL_HIGH>,
				     <GIC_SPI 123 IRQ_TYPE_LEVEL_HIGH>;
			clocks = <&fin_pll>, <&clock_peris PCLK_MCT>;
			clock-names = "fin_pll", "mct";
			status = "disabled";
		};

		/*
		 * Block power domains without a driver yet. S-Boot leaves them on;
		 * declared here, genpd powers them off as unused, as Samsung's
		 * kernel kept them off while idle. Parents as in Samsung's DT:
		 * CAM0 and ISP1 under CAM1, ISP0 under ISP1.
		 */
		pd_aud: power-domain@105c4000 {
			compatible = "samsung,exynos5433-pd";
			reg = <0x105c4000 0x20>;
			#power-domain-cells = <0>;
			label = "AUD";
		};

		pd_cam0: power-domain@105c4040 {
			compatible = "samsung,exynos5433-pd";
			reg = <0x105c4040 0x20>;
			#power-domain-cells = <0>;
			label = "CAM0";
			power-domains = <&pd_cam1>;
		};

		pd_cam1: power-domain@105c4060 {
			compatible = "samsung,exynos5433-pd";
			reg = <0x105c4060 0x20>;
			#power-domain-cells = <0>;
			label = "CAM1";
		};

		pd_isp0: power-domain@105c4140 {
			compatible = "samsung,exynos5433-pd";
			reg = <0x105c4140 0x20>;
			#power-domain-cells = <0>;
			label = "ISP0";
			power-domains = <&pd_isp1>;
		};

		pd_isp1: power-domain@105c4180 {
			compatible = "samsung,exynos5433-pd";
			reg = <0x105c4180 0x20>;
			#power-domain-cells = <0>;
			label = "ISP1";
			power-domains = <&pd_cam1>;
		};

		pd_mfc: power-domain@105c41a0 {
			compatible = "samsung,exynos5433-pd";
			reg = <0x105c41a0 0x20>;
			#power-domain-cells = <0>;
			label = "MFC";
		};

		pd_mscl: power-domain@105c41c0 {
			compatible = "samsung,exynos5433-pd";
			reg = <0x105c41c0 0x20>;
			#power-domain-cells = <0>;
			label = "MSCL";
		};

		rtc: rtc@10590000 {
			compatible = "samsung,s3c6410-rtc";
			reg = <0x10590000 0x100>;
			interrupts = <GIC_SPI 355 IRQ_TYPE_LEVEL_HIGH>,
				     <GIC_SPI 356 IRQ_TYPE_LEVEL_HIGH>;
			clocks = <&clock_ccore PCLK_RTC>;
			clock-names = "rtc";
			status = "disabled";
		};

		watchdog: watchdog@101d0000 {
			compatible = "samsung,exynos7-wdt";
			reg = <0x101d0000 0x100>;
			interrupts = <GIC_SPI 110 IRQ_TYPE_LEVEL_HIGH>;
			clocks = <&clock_peris PCLK_WDT>;
			clock-names = "watchdog";
			samsung,syscon-phandle = <&pmu_system_controller>;
			status = "disabled";
		};

		gpu: gpu@14ac0000 {
			compatible = "samsung,exynos5433-mali", "arm,mali-t760";
			reg = <0x14ac0000 0x5000>;
			interrupts = <GIC_SPI 241 IRQ_TYPE_LEVEL_HIGH>,
				     <GIC_SPI 242 IRQ_TYPE_LEVEL_HIGH>,
				     <GIC_SPI 240 IRQ_TYPE_LEVEL_HIGH>;
			interrupt-names = "job", "mmu", "gpu";
			clocks = <&cmu_g3d CLK_ACLK_G3D>,
				 <&cmu_g3d CLK_PCLK_SYSREG_G3D>;
			clock-names = "core", "bus";
			power-domains = <&pd_g3d>;
			#cooling-cells = <2>;
			status = "disabled";
			/* TODO: operating points for DVFS, cooling device */
		};

		mmc_0: mmc@15740000 {
			compatible = "samsung,exynos7-dw-mshc-smu";
			interrupts = <GIC_SPI 201 IRQ_TYPE_LEVEL_HIGH>;
			#address-cells = <1>;
			#size-cells = <0>;
			reg = <0x15740000 0x2000>;
			clocks = <&clock_fsys1 ACLK_MMC0>,
				 <&clock_top1 CLK_SCLK_MMC0>;
			clock-names = "biu", "ciu";
			fifo-depth = <0x40>;
			status = "disabled";
		};

		mmc_1: mmc@15750000 {
			compatible = "samsung,exynos7-dw-mshc";
			interrupts = <GIC_SPI 202 IRQ_TYPE_LEVEL_HIGH>;
			#address-cells = <1>;
			#size-cells = <0>;
			reg = <0x15750000 0x2000>;
			clocks = <&clock_fsys1 ACLK_MMC1>,
				 <&clock_top1 CLK_SCLK_MMC1>;
			clock-names = "biu", "ciu";
			fifo-depth = <0x40>;
			status = "disabled";
		};

		mmc_2: mmc@15560000 {
			compatible = "samsung,exynos7-dw-mshc-smu";
			interrupts = <GIC_SPI 216 IRQ_TYPE_LEVEL_HIGH>;
			#address-cells = <1>;
			#size-cells = <0>;
			reg = <0x15560000 0x2000>;
			clocks = <&clock_fsys0 ACLK_MMC2>,
				 <&clock_top1 CLK_SCLK_MMC2>;
			clock-names = "biu", "ciu";
			fifo-depth = <0x40>;
			status = "disabled";
		};

		adc: adc@13620000 {
			compatible = "samsung,exynos7-adc";
			reg = <0x13620000 0x100>;
			interrupts = <GIC_SPI 448 IRQ_TYPE_LEVEL_HIGH>;
			clocks = <&clock_peric0 PCLK_ADCIF>;
			clock-names = "adc";
			#io-channel-cells = <1>;
			status = "disabled";
		};

		pwm: pwm@136c0000 {
			compatible = "samsung,exynos4210-pwm";
			reg = <0x136c0000 0x100>;
			interrupts = <GIC_SPI 449 IRQ_TYPE_LEVEL_HIGH>,
				     <GIC_SPI 450 IRQ_TYPE_LEVEL_HIGH>,
				     <GIC_SPI 451 IRQ_TYPE_LEVEL_HIGH>,
				     <GIC_SPI 452 IRQ_TYPE_LEVEL_HIGH>,
				     <GIC_SPI 453 IRQ_TYPE_LEVEL_HIGH>;
			samsung,pwm-outputs = <0>, <1>, <2>, <3>;
			#pwm-cells = <3>;
			clocks = <&clock_peric0 PCLK_PWM>;
			clock-names = "timers";
		};

		sysmmu_disp_ro: iommu@13a00000 {
			compatible = "samsung,exynos7420-sysmmu";
			reg = <0x13a00000 0x1000>;
			interrupts = <GIC_SPI 176 IRQ_TYPE_LEVEL_HIGH>;
			clocks = <&cmu_disp CLK_ACLK_DISP_RO_SYSMMU>,
				 <&cmu_disp CLK_PCLK_DISP_RO_SYSMMU>,
				 <&cmu_disp CLK_ACLK_DECON0>;
			clock-names = "aclk", "pclk", "master";
			#iommu-cells = <0>;
			status = "disabled";
		};

		sysmmu_disp_rw: iommu@13a10000 {
			compatible = "samsung,exynos7420-sysmmu";
			reg = <0x13a10000 0x1000>;
			interrupts = <GIC_SPI 179 IRQ_TYPE_LEVEL_HIGH>;
			clocks = <&cmu_disp CLK_ACLK_DISP_RW_SYSMMU>,
				 <&cmu_disp CLK_PCLK_DISP_RW_SYSMMU>,
				 <&cmu_disp CLK_ACLK_DECON0>;
			clock-names = "aclk", "pclk", "master";
			#iommu-cells = <0>;
			status = "disabled";
		};

		decon: decon@13930000 {
			compatible = "samsung,exynos7-decon";
			reg = <0x13930000 0x10000>;
			interrupts = <GIC_SPI 190 IRQ_TYPE_LEVEL_HIGH>,
				     <GIC_SPI 189 IRQ_TYPE_LEVEL_HIGH>,
				     <GIC_SPI 188 IRQ_TYPE_LEVEL_HIGH>;
			interrupt-names = "fifo", "vsync", "lcd_sys";
			clocks = <&cmu_disp CLK_PCLK_DECON0>,
				 <&cmu_disp CLK_ACLK_DECON0>,
				 <&cmu_disp CLK_SCLK_DECON0_ECLK>,
				 <&cmu_disp CLK_SCLK_DECON0_VCLK>;
			clock-names = "pclk_decon0", "aclk_decon0",
				      "decon0_eclk", "decon0_vclk";
			iommus = <&sysmmu_disp_ro>, <&sysmmu_disp_rw>;
			status = "disabled";
		};

		tmuctrl_0: tmu@10060000 {
			compatible = "samsung,exynos7-tmu";
			reg = <0x10060000 0x200>;
			interrupts = <GIC_SPI 108 IRQ_TYPE_LEVEL_HIGH>;
			clocks = <&clock_peris PCLK_TMU>,
				 <&clock_peris SCLK_TMU>;
			clock-names = "tmu_apbif", "tmu_sclk";
			#thermal-sensor-cells = <0>;
		};

		ufs: ufs@15570000 {
			compatible = "samsung,exynos7-ufs";
			reg = <0x15570000 0x100>,  /* 0: HCI standard */
				<0x15570100 0x100>,  /* 1: Vendor specificed */
				<0x15571000 0x200>,  /* 2: UNIPRO */
				<0x15572000 0x300>;  /* 3: UFS protector */
			reg-names = "hci", "vs_hci", "unipro", "ufsp";
			interrupts = <GIC_SPI 200 IRQ_TYPE_LEVEL_HIGH>;
			clocks = <&clock_fsys1 ACLK_UFS20_LINK>,
				<&clock_fsys1 SCLK_UFSUNIPRO20_USER>;
			clock-names = "core_clk", "sclk_unipro_main";
			freq-table-hz = <0 0>, <0 0>;
			pinctrl-names = "default";
			pinctrl-0 = <&ufs_rst_n &ufs_refclk_out>;
			phys = <&ufs_phy>;
			phy-names = "ufs-phy";
			status = "disabled";
		};

		ufs_phy: ufs-phy@15571800 {
			compatible = "samsung,exynos7-ufs-phy";
			reg = <0x15571800 0x240>;
			reg-names = "phy-pma";
			samsung,pmu-syscon = <&pmu_system_controller>;
			#phy-cells = <0>;
			clocks = <&clock_fsys1 SCLK_COMBO_PHY_EMBEDDED_26M>,
				 <&clock_fsys1 PHYCLK_UFS20_RX1_SYMBOL_USER>,
				 <&clock_fsys1 PHYCLK_UFS20_RX0_SYMBOL_USER>,
				 <&clock_fsys1 PHYCLK_UFS20_TX0_SYMBOL_USER>;
			clock-names = "ref_clk", "rx1_symbol_clk",
				      "rx0_symbol_clk",
				      "tx0_symbol_clk";
		};

		usbdrd_phy: phy@15500000 {
			compatible = "samsung,exynos7-usbdrd-phy";
			reg = <0x15500000 0x100>;
			clocks = <&clock_fsys0 ACLK_USBDRD300>,
			       <&clock_fsys0 OSCCLK_PHY_CLKOUT_USB30_PHY>,
			       <&clock_fsys0 PHYCLK_USBDRD300_UDRD30_PHYCLK_USER>,
			       <&clock_fsys0 PHYCLK_USBDRD300_UDRD30_PIPE_PCLK_USER>,
			       <&clock_fsys0 SCLK_USBDRD300_REFCLK>;
			clock-names = "phy", "ref", "phy_utmi", "phy_pipe", "itp";
			samsung,pmu-syscon = <&pmu_system_controller>;
			#phy-cells = <1>;
		};

		usbdrd: usb@15400000 {
			compatible = "samsung,exynos7-dwusb3";
			clocks = <&clock_fsys0 ACLK_USBDRD300>,
			       <&clock_fsys0 SCLK_USBDRD300_SUSPENDCLK>,
			       <&clock_fsys0 ACLK_AXIUS_USBDRD30X_FSYS0X>;
			clock-names = "usbdrd30", "usbdrd30_susp_clk",
				"usbdrd30_axius_clk";
			#address-cells = <1>;
			#size-cells = <1>;
			ranges = <0x0 0x15400000 0x10000>;

			usb@0 {
				compatible = "snps,dwc3";
				reg = <0x0 0x10000>;
				interrupts = <GIC_SPI 223 IRQ_TYPE_LEVEL_HIGH>;
				phys = <&usbdrd_phy 0>, <&usbdrd_phy 1>;
				phy-names = "usb2-phy", "usb3-phy";
			};
		};
	};

	thermal-zones {
		/*
		 * The zone type is the node name; Samsung's Android thermal
		 * HAL looks for the 3.10 name "exynos-therm".
		 */
		atlas_thermal: exynos-therm {
			/* The stock trips and caps; the states index the OPP tables. */
			polling-delay-passive = <100>; /* milliseconds */
			polling-delay = <1000>; /* milliseconds */
			thermal-sensors = <&tmuctrl_0>;
			#include "exynos7-trip-points.dtsi"

			cooling-maps {
				map0 {
					/* 75 C: A57 1704 MHz */
					trip = <&cpu_alert0>;
					cooling-device = <&cpu_atlas0 1 1>,
						 <&cpu_atlas1 1 1>,
						 <&cpu_atlas2 1 1>,
						 <&cpu_atlas3 1 1>;
				};
				map1 {
					/* 80 C: A57 1300 MHz, A53 1400 MHz, GPU 544 MHz */
					trip = <&cpu_alert1>;
					cooling-device = <&cpu_atlas0 5 5>,
						 <&cpu_atlas1 5 5>,
						 <&cpu_atlas2 5 5>,
						 <&cpu_atlas3 5 5>,
						 <&cpu_apollo0 1 1>,
						 <&cpu_apollo1 1 1>,
						 <&cpu_apollo2 1 1>,
						 <&cpu_apollo3 1 1>,
						 <&gpu 2 2>;
				};
				map2 {
					/* 85 C: A57 800 MHz, A53 1200 MHz, GPU 420 MHz */
					trip = <&cpu_alert2>;
					cooling-device = <&cpu_atlas0 10 10>,
						 <&cpu_atlas1 10 10>,
						 <&cpu_atlas2 10 10>,
						 <&cpu_atlas3 10 10>,
						 <&cpu_apollo0 3 3>,
						 <&cpu_apollo1 3 3>,
						 <&cpu_apollo2 3 3>,
						 <&cpu_apollo3 3 3>,
						 <&gpu 3 3>;
				};
				map3 {
					/* 90 C: A53 1000 MHz, GPU 266 MHz */
					trip = <&cpu_alert3>;
					cooling-device = <&cpu_apollo0 5 5>,
						 <&cpu_apollo1 5 5>,
						 <&cpu_apollo2 5 5>,
						 <&cpu_apollo3 5 5>,
						 <&gpu 5 5>;
				};
				map4 {
					/* 95 C: A53 400 MHz */
					trip = <&cpu_alert4>;
					cooling-device = <&cpu_apollo0 11 11>,
						 <&cpu_apollo1 11 11>,
						 <&cpu_apollo2 11 11>,
						 <&cpu_apollo3 11 11>;
				};
			};
		};
	};

	/* CPU PMU interrupts as in the stock 3.10 arm-pmu node */
	pmu-a53 {
		compatible = "arm,cortex-a53-pmu";
		interrupts = <GIC_SPI 32 IRQ_TYPE_LEVEL_HIGH>,
			     <GIC_SPI 33 IRQ_TYPE_LEVEL_HIGH>,
			     <GIC_SPI 34 IRQ_TYPE_LEVEL_HIGH>,
			     <GIC_SPI 35 IRQ_TYPE_LEVEL_HIGH>;
		interrupt-affinity = <&cpu_apollo0>, <&cpu_apollo1>,
				     <&cpu_apollo2>, <&cpu_apollo3>;
	};

	pmu-a57 {
		compatible = "arm,cortex-a57-pmu";
		interrupts = <GIC_SPI 56 IRQ_TYPE_LEVEL_HIGH>,
			     <GIC_SPI 57 IRQ_TYPE_LEVEL_HIGH>,
			     <GIC_SPI 58 IRQ_TYPE_LEVEL_HIGH>,
			     <GIC_SPI 59 IRQ_TYPE_LEVEL_HIGH>;
		interrupt-affinity = <&cpu_atlas0>, <&cpu_atlas1>,
				     <&cpu_atlas2>, <&cpu_atlas3>;
	};

	timer {
		compatible = "arm,armv8-timer";
		interrupts = <GIC_PPI 13
				(GIC_CPU_MASK_SIMPLE(8) | IRQ_TYPE_LEVEL_LOW)>,
			     <GIC_PPI 14
				(GIC_CPU_MASK_SIMPLE(8) | IRQ_TYPE_LEVEL_LOW)>,
			     <GIC_PPI 11
				(GIC_CPU_MASK_SIMPLE(8) | IRQ_TYPE_LEVEL_LOW)>,
			     <GIC_PPI 10
				(GIC_CPU_MASK_SIMPLE(8) | IRQ_TYPE_LEVEL_LOW)>;
	};
};

#include "exynos7-pinctrl.dtsi"
#include "arm/samsung/exynos-syscon-restart.dtsi"
